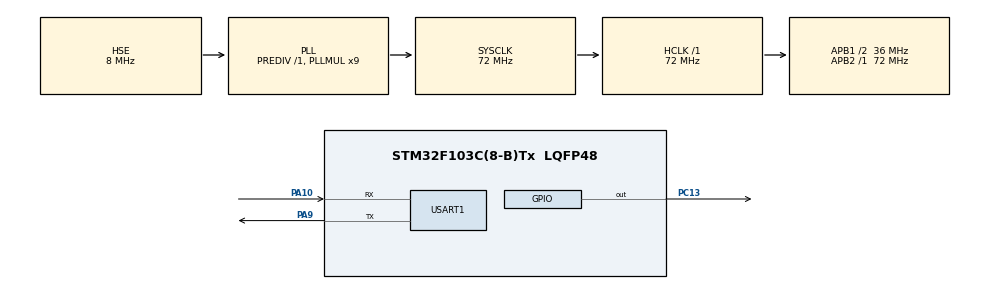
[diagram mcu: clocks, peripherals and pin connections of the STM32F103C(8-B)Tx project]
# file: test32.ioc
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Mcu.Family=STM32F1
Mcu.Name=STM32F103C(8-B)Tx
Mcu.Package=LQFP48
NVIC.PriorityGroup=NVIC_PRIORITYGROUP_4
NVIC.USART1_IRQn=true\:0\:0\:false\:false\:true\:true\:true\:true
PA10.Mode=Asynchronous
PA10.Signal=USART1_RX
PA13.Mode=Serial_Wire
PA13.Signal=SYS_JTMS-SWDIO
PA14.Mode=Serial_Wire
PA14.Signal=SYS_JTCK-SWCLK
PA9.Mode=Asynchronous
PA9.Signal=USART1_TX
PC13-TAMPER-RTC.Signal=GPIO_Output
PD0-OSC_IN.Mode=HSE-External-Oscillator
PD0-OSC_IN.Signal=RCC_OSC_IN
PD1-OSC_OUT.Mode=HSE-External-Oscillator
PD1-OSC_OUT.Signal=RCC_OSC_OUT
ProjectManager.HeapSize=0x200
ProjectManager.StackSize=0x400
ProjectManager.TargetToolchain=Makefile
RCC.AHBFreq_Value=72000000
RCC.APB1CLKDivider=RCC_HCLK_DIV2
RCC.APB1Freq_Value=36000000
RCC.APB1TimFreq_Value=72000000
RCC.APB2Freq_Value=72000000
RCC.APB2TimFreq_Value=72000000
RCC.HCLKFreq_Value=72000000
RCC.PLLMUL=RCC_PLL_MUL9
RCC.PLLSourceVirtual=RCC_PLLSOURCE_HSE
RCC.SYSCLKFreq_VALUE=72000000
RCC.SYSCLKSource=RCC_SYSCLKSOURCE_PLLCLK
RCC.USBFreq_Value=72000000
USART1.VirtualMode=VM_ASYNC
board=custom

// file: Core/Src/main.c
/* USER CODE BEGIN Header */
/**
  ******************************************************************************
  * @file           : main.c
  * @brief          : Main program body
  ******************************************************************************
  * @attention
  *
  * Copyright (c) 2026 STMicroelectronics.
  * All rights reserved.
  *
  * This software is licensed under terms that can be found in the LICENSE file
  * in the root directory of this software component.
  * If no LICENSE file comes with this software, it is provided AS-IS.
  *
  ******************************************************************************
  */
/* USER CODE END Header */
#include "main.h"
#include "usart.h"
#include "gpio.h"

/* USER CODE BEGIN Includes */
#include "app_echo.h"
/* USER CODE END Includes */

/* USER CODE BEGIN PV */
/* LED 闪烁节拍状态已移入 app_led.c 的 static s_last_tick，此处不再保留第二条节拍变量 */
/* USER CODE END PV */

void SystemClock_Config(void);

int main(void)
{

  /* MCU Configuration--------------------------------------------------------*/

  /* Reset of all peripherals, Initializes the Flash interface and the Systick. */
  HAL_Init();

  /* Configure the system clock */
  SystemClock_Config();

  /* Initialize all configured peripherals */
  MX_GPIO_Init();
  MX_USART1_UART_Init();
  /* USER CODE BEGIN 2 */
  /* 上电先熄灭 LED（若原理图核对为低有效则置高） */
#if LED_ACTIVE_LOW
  HAL_GPIO_WritePin(LED_GPIO_PORT, LED_GPIO_PIN, GPIO_PIN_SET);
#else
  HAL_GPIO_WritePin(LED_GPIO_PORT, LED_GPIO_PIN, GPIO_PIN_RESET);
#endif

  /* 启动 USART1 回显通道（DMA 循环接收 + IDLE 中断分段），失败进入错误处理 */
  if (app_echo_init() != HAL_OK)
  {
    Error_Handler();
  }

  /* USER CODE END 2 */

  /* Infinite loop */
  while (1)
  {

    /* USER CODE BEGIN 3 */
    /* LED 状态统一由 MODULES 层 app_led 模块管理：
     * 常亮 / 常灭 / 周期闪烁分别由串口命令 LED_ON / LED_OFF / BLINK:<ms> 控制，
     * 闪烁节拍在 app_led_poll() 内用 HAL_GetTick 差值推进。
     * 本处不再保留第二条 PC13 节拍（否则与命令互相覆盖，且周期宏已随台账收敛）。 */
    /* USART1 回显：把中断收到的字节原样发回 PC */
    app_echo_poll();
 //ABCDEFG

  }
  /* USER CODE END 3 */
}

void SystemClock_Config(void)
{
  RCC_OscInitTypeDef RCC_OscInitStruct = {0};
  RCC_ClkInitTypeDef RCC_ClkInitStruct = {0};

  /** Initializes the RCC Oscillators according to the specified parameters
  * in the RCC_OscInitTypeDef structure.
  */
  RCC_OscInitStruct.OscillatorType = RCC_OSCILLATORTYPE_HSE;
  RCC_OscInitStruct.HSEState = RCC_HSE_ON;
  RCC_OscInitStruct.HSEPredivValue = RCC_HSE_PREDIV_DIV1;
  RCC_OscInitStruct.HSIState = RCC_HSI_ON;
  RCC_OscInitStruct.PLL.PLLState = RCC_PLL_ON;
  RCC_OscInitStruct.PLL.PLLSource = RCC_PLLSOURCE_HSE;
  RCC_OscInitStruct.PLL.PLLMUL = RCC_PLL_MUL9;
  if (HAL_RCC_OscConfig(&RCC_OscInitStruct) != HAL_OK)
  {
    Error_Handler();
  }

  /** Initializes the CPU, AHB and APB buses clocks
  */
  RCC_ClkInitStruct.ClockType = RCC_CLOCKTYPE_HCLK|RCC_CLOCKTYPE_SYSCLK
                              |RCC_CLOCKTYPE_PCLK1|RCC_CLOCKTYPE_PCLK2;
  RCC_ClkInitStruct.SYSCLKSource = RCC_SYSCLKSOURCE_PLLCLK;
  RCC_ClkInitStruct.AHBCLKDivider = RCC_SYSCLK_DIV1;
  RCC_ClkInitStruct.APB1CLKDivider = RCC_HCLK_DIV2;
  RCC_ClkInitStruct.APB2CLKDivider = RCC_HCLK_DIV1;

  if (HAL_RCC_ClockConfig(&RCC_ClkInitStruct, FLASH_LATENCY_2) != HAL_OK)
  {
    Error_Handler();
  }
}

void Error_Handler(void)
{
  __disable_irq();
  while (1)
  {
  }
}
